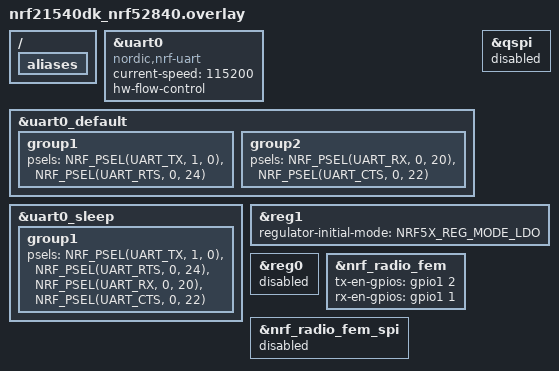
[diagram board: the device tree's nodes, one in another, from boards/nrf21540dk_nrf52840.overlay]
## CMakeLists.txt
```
# SPDX-License-Identifier: Apache-2.0

cmake_minimum_required(VERSION 3.20.0)

find_package(Zephyr REQUIRED HINTS $ENV{ZEPHYR_BASE})
project(hci_uart)

test_sysbuild()

target_sources(app PRIVATE src/main.c src/board.c)
```

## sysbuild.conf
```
# Sysbuild configuration file.

# Enable MCUboot per default for this sample.
SB_CONFIG_PARTITION_MANAGER=y
SB_CONFIG_BOOTLOADER_MCUBOOT=y

SB_CONFIG_MCUBOOT_MODE_SINGLE_APP=y
```

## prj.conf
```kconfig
CONFIG_CONSOLE=n
CONFIG_STDOUT_CONSOLE=n
CONFIG_UART_CONSOLE=n
CONFIG_GPIO=y
CONFIG_SERIAL=y
CONFIG_UART_INTERRUPT_DRIVEN=y
CONFIG_BT=y
CONFIG_BT_HCI_RAW=y
CONFIG_BT_HCI_RAW_H4=y
CONFIG_BT_HCI_RAW_H4_ENABLE=y
CONFIG_BT_BUF_ACL_RX_SIZE=255
CONFIG_BT_BUF_CMD_TX_SIZE=255
CONFIG_BT_BUF_EVT_DISCARDABLE_SIZE=255
CONFIG_BT_CTLR_ASSERT_HANDLER=y
CONFIG_BT_MAX_CONN=16
CONFIG_BT_TINYCRYPT_ECC=n
CONFIG_BT_CTLR_DTM_HCI=y

CONFIG_SYSTEM_WORKQUEUE_STACK_SIZE=512

# Workaround: Unable to allocate command buffer when using K_NO_WAIT since
# Host number of completed commands does not follow normal flow control.
CONFIG_BT_BUF_CMD_TX_COUNT=10

CONFIG_CLOCK_CONTROL_NRF_K32SRC_XTAL=n
CONFIG_CLOCK_CONTROL_NRF_K32SRC_RC=y
CONFIG_CLOCK_CONTROL_NRF_K32SRC_500PPM=y

#####################################################
###### To be compatible with AzureWave module #######
####### by enbaling PARAM REQ to support IOS ########
#####################################################

# BT_CTLR_CONN_PARAM_REQ_SUPPORT=y
# CONFIG_BOOTLOADER_MCUBOOT=y
# CONFIG_SINGLE_APPLICATION_SLOT=y

CONFIG_BT_CTLR_CONN_PARAM_REQ=y
CONFIG_BT_CTLR_ADVANCED_FEATURES=n
CONFIG_BT_CTLR_PER_INIT_FEAT_XCHG=y

CONFIG_BT_PHY_UPDATE=y
CONFIG_BT_CTLR_PHY_2M=y
CONFIG_BT_CTLR_PHY_CODED=y

# CONFIG_BT_BUF_EVT_RX_COUNT=16
CONFIG_BT_BUF_EVT_RX_COUNT=8

CONFIG_BT_BUF_EVT_RX_SIZE=255
CONFIG_BT_BUF_ACL_RX_SIZE=255
CONFIG_BT_BUF_ACL_TX_SIZE=251
CONFIG_BT_BUF_CMD_TX_SIZE=255

# Host and Controller common dependencies
CONFIG_BT_EXT_ADV=n
CONFIG_BT_PER_ADV=n
CONFIG_BT_PER_ADV_SYNC=n
# CONFIG_BT_PER_ADV_SYNC_MAX=2

# Broadcast and Connected ISO
# CONFIG_BT_ISO_BROADCASTER=y
# CONFIG_BT_ISO_SYNC_RECEIVER=y
# CONFIG_BT_ISO_CENTRAL=y
# CONFIG_BT_ISO_PERIPHERAL=y

# ISO Streams
# CONFIG_BT_ISO_MAX_CHAN=2

# Controller
CONFIG_BT_LL_SW_SPLIT=y
CONFIG_BT_CTLR_ASSERT_HANDLER=y
CONFIG_BT_CTLR_DTM_HCI=n

# Rx ACL and Adv Reports
CONFIG_BT_CTLR_RX_BUFFERS=9
CONFIG_BT_CTLR_DATA_LENGTH_MAX=251

# Advertising Sets and Extended Scanning
CONFIG_BT_CTLR_ADV_EXT=n
# CONFIG_BT_CTLR_ADV_EXT=y
# CONFIG_BT_CTLR_ADV_SET=3
# CONFIG_BT_CTLR_ADV_DATA_LEN_MAX=191
# CONFIG_BT_CTLR_SCAN_DATA_LEN_MAX=1650

CONFIG_BT_CTLR_ADVANCED_FEATURES=n
# CONFIG_BT_CTLR_ADV_AUX_SET=3
CONFIG_BT_CTLR_ADV_AUX_PDU_BACK2BACK=n
# CONFIG_BT_CTLR_ADV_SYNC_SET=3
CONFIG_BT_CTLR_ADV_SYNC_PDU_BACK2BACK=n
# CONFIG_BT_CTLR_ADV_DATA_BUF_MAX=6

# Increase the below to receive interleaved advertising chains
CONFIG_BT_CTLR_SCAN_AUX_SET=1

CONFIG_BT_CTLR_ADV_RESERVE_MAX=n
CONFIG_BT_CTLR_CENTRAL_RESERVE_MAX=n
CONFIG_BT_CTLR_SLOT_RESERVATION_UPDATE=n
CONFIG_BT_CTLR_SCAN_UNRESERVED=n
CONFIG_BT_TICKER_NEXT_SLOT_GET_MATCH=n
CONFIG_BT_TICKER_EXT=n
CONFIG_BT_TICKER_EXT_SLOT_WINDOW_YIELD=n

# Control Procedure
CONFIG_BT_CTLR_LLCP_LOCAL_PROC_CTX_BUF_NUM=6

# Direction Finding
CONFIG_BT_CTLR_DF=n
# CONFIG_BT_CTLR_DF_PER_ADV_CTE_NUM_MAX=3
# CONFIG_BT_CTLR_DF_PER_SCAN_CTE_NUM_MAX=3

# Direction Finding Tx
CONFIG_BT_CTLR_DF_CTE_TX=n
# CONFIG_BT_CTLR_DF_CONN_CTE_TX=y
# CONFIG_BT_CTLR_DF_ANT_SWITCH_TX=y
# CONFIG_BT_CTLR_DF_CONN_CTE_RSP=y

# Direction Finding Rx
CONFIG_BT_CTLR_DF_CTE_RX=n
# CONFIG_BT_CTLR_DF_CONN_CTE_RX=y
# CONFIG_BT_CTLR_DF_ANT_SWITCH_RX=y
# CONFIG_BT_CTLR_DF_CONN_CTE_REQ=y

# ISO Broadcaster Controller
CONFIG_BT_CTLR_ADV_EXT=n
# CONFIG_BT_CTLR_ADV_PERIODIC=y
# CONFIG_BT_CTLR_ADV_ISO=y
# CONFIG_BT_CTLR_ADV_ISO_PDU_LEN_MAX=247
# CONFIG_BT_CTLR_ADV_ISO_STREAM_MAX=2

# ISO Receive Controller
CONFIG_BT_CTLR_ADV_EXT=n
# CONFIG_BT_CTLR_SYNC_PERIODIC=y
# CONFIG_BT_CTLR_SYNC_ISO=y
# CONFIG_BT_CTLR_SYNC_ISO_PDU_LEN_MAX=251
# CONFIG_BT_CTLR_SYNC_ISO_STREAM_MAX=2

# ISO Connection Oriented
CONFIG_BT_CTLR_CENTRAL_ISO=n
CONFIG_BT_CTLR_PERIPHERAL_ISO=n
# CONFIG_BT_CTLR_CONN_ISO_SDU_LEN_MAX=247
# CONFIG_BT_CTLR_CONN_ISO_PDU_LEN_MAX=251

# ISO Transmissions
# CONFIG_BT_CTLR_ISO_TX_BUFFERS=8
# CONFIG_BT_CTLR_ISO_TX_BUFFER_SIZE=255
# CONFIG_BT_CTLR_ISOAL_SOURCES=2

# ISO Receptions
# CONFIG_BT_CTLR_ISO_RX_BUFFERS=8
# CONFIG_BT_CTLR_ISOAL_SINKS=2

# Tx Power Dynamic Control
CONFIG_BT_CTLR_TX_PWR_DYNAMIC_CONTROL=y
# CONFIG_BT_CTLR_TX_PWR_PLUS_8=y
# CONFIG_BT_CTLR_TX_PWR_0=y
CONFIG_BT_CTLR_TX_PWR_MINUS_20=y


#############################################################
CONFIG_MCUBOOT_EXTRA_IMGTOOL_ARGS="--version 1.0.3"


# If want to enable logging for debugging stack overflows etc, uncomment below

# # Enable logging via SEGGER RTT so logs appear over J-Link RTT
# CONFIG_LOG=y
# # 2 = Info (disable DBG to reduce log volume).
# CONFIG_LOG_DEFAULT_LEVEL=2
# CONFIG_LOG_BACKEND_RTT=y
# # CONFIG_SEGGER_RTT=y
# # Flush log immediately which helps for early boot / crashes
# # Ensure immediate mode is disabled to avoid blocking contexts
# CONFIG_LOG_MODE_IMMEDIATE=n

# # Increase log processing thread stack to avoid overflow (seen at runtime)
# CONFIG_LOG_PROCESS_THREAD_STACK_SIZE=4096

# # # Enable thread stack debugging to catch overflows and identify threads
# # # Provides runtime info about which thread overflowed and stack usage
# CONFIG_THREAD_MONITOR=y
# CONFIG_THREAD_NAME=y
# CONFIG_STACK_CANARIES=y

# # Increase some stack sizes that commonly overflow in Bluetooth controller use
# # Increase HCI TX thread stack
# CONFIG_BT_HCI_TX_STACK_SIZE_WITH_PROMPT=y
# CONFIG_BT_HCI_TX_STACK_SIZE=4096
# # Increase system workqueue stack
# CONFIG_SYSTEM_WORKQUEUE_STACK_SIZE=1024
# # Increase main thread stack as a precaution
# CONFIG_MAIN_STACK_SIZE=4096

# CONFIG_LOG_BUFFER_SIZE=8192
# CONFIG_SEGGER_RTT_BUFFER_SIZE_UP=8192
# CONFIG_LOG_BACKEND_RTT_MODE_DROP=n
```

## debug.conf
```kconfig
CONFIG_ASSERT=y

CONFIG_THREAD_NAME=y
CONFIG_THREAD_ANALYZER=y
CONFIG_THREAD_ANALYZER_AUTO=y
CONFIG_THREAD_ANALYZER_RUN_UNLOCKED=y

CONFIG_HW_STACK_PROTECTION=y

CONFIG_CONSOLE=y
CONFIG_LOG=y
CONFIG_LOG_BUFFER_SIZE=4096
CONFIG_RTT_CONSOLE=y
CONFIG_LOG_BACKEND_RTT=y
CONFIG_LOG_BACKEND_RTT_MODE_DROP=n
CONFIG_USE_SEGGER_RTT=y
CONFIG_SEGGER_RTT_BUFFER_SIZE_UP=4096
CONFIG_LOG_BACKEND_SHOW_COLOR=n
CONFIG_LOG_PROCESS_THREAD_STACK_SIZE=1024

CONFIG_LOG_DEFAULT_LEVEL=3
```

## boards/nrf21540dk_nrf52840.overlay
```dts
// To get started, press Ctrl+Space to bring up the completion menu and view the available nodes.

// You can also use the buttons in the sidebar to perform actions on nodes.
// Actions currently available include:

// * Enabling / disabling the node
// * Adding the bus to a bus
// * Removing the node
// * Connecting ADC channels

// For more help, browse the DeviceTree documentation at https://docs.zephyrproject.org/latest/guides/dts/index.html
// You can also visit the nRF DeviceTree extension documentation at https://docs.nordicsemi.com/bundle/nrf-connect-vscode/page/guides/ncs_configure_app.html#devicetree-support-in-the-extension

/* SPDX-License-Identifier: Apache-2.0 */

&uart0 {
	compatible = "nordic,nrf-uart";
	current-speed = <115200>;
	status = "okay";
	hw-flow-control;
};

&uart0_default {
	group1 {
		psels = <NRF_PSEL(UART_TX, 1, 0)>, <NRF_PSEL(UART_RTS, 0, 24)>;
		// psels = <NRF_PSEL(UART_TX, 1, 3)>, <NRF_PSEL(UART_RTS, 1, 4)>;
	};

	group2 {
		psels = <NRF_PSEL(UART_RX, 0, 20)>, <NRF_PSEL(UART_CTS, 0, 22)>;
		// psels = <NRF_PSEL(UART_RX, 1, 5)>, <NRF_PSEL(UART_CTS, 1, 6)>;
	};
};

&uart0_sleep {
	group1 {
		psels = <NRF_PSEL(UART_TX, 1, 0)>, <NRF_PSEL(UART_RTS, 0, 24)>, <NRF_PSEL(UART_RX, 0, 20)>, <NRF_PSEL(UART_CTS, 0, 22)>;
		// psels = <NRF_PSEL(UART_TX, 1, 3)>, <NRF_PSEL(UART_RTS, 1, 4)>, <NRF_PSEL(UART_RX, 1, 5)>, <NRF_PSEL(UART_CTS, 1, 6)>;
	};
};

&qspi {
	status = "disabled";
};
/delete-node/ &button2;

/ {
	aliases {
		/delete-property/ sw2;
	};
};

&reg1 {
	regulator-initial-mode = <NRF5X_REG_MODE_LDO>;
    // regulator-initial-mode = <NRF5X_REG_MODE_DCDC>;
};
&reg0 {
    status = "disabled";
    // status = "okay";
};
&nrf_radio_fem {
	tx-en-gpios = <&gpio1 2 GPIO_ACTIVE_HIGH>;
	rx-en-gpios = <&gpio1 1 GPIO_ACTIVE_HIGH>;
	/delete-property/ pdn-gpios;
	/delete-property/ spi-if;
	/delete-property/ mode-gpios;
	/delete-property/ ant-sel-gpios;
};

&nrf_radio_fem_spi {
	status = "disabled";
};
```

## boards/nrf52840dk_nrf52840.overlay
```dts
/* SPDX-License-Identifier: Apache-2.0 */

// &uart0 {
// 	compatible = "nordic,nrf-uart";
// 	current-speed = <115200>;
// 	status = "okay";
// 	hw-flow-control;
// };

// &uart0_default {
// 	group1 {
// 		psels = <NRF_PSEL(UART_TX, 1, 0)>, <NRF_PSEL(UART_RTS, 0, 24)>;
// 	};

// 	group2 {
// 		psels = <NRF_PSEL(UART_RX, 0, 20)>, <NRF_PSEL(UART_CTS, 0, 22)>;
// 	};
// };

// &uart0_sleep {
// 	group1 {
// 		psels = <NRF_PSEL(UART_TX, 1, 0)>, <NRF_PSEL(UART_RTS, 0, 24)>, <NRF_PSEL(UART_RX, 0, 20)>, <NRF_PSEL(UART_CTS, 0, 22)>;
// 	};
// };

// &qspi {
// 	status = "disabled";
// };
// /delete-node/ &button2;

// / {
// 	aliases {
// 		/delete-property/ sw2;
// 	};
// };

// &reg1 {
// 	regulator-initial-mode = <NRF5X_REG_MODE_LDO>;
//     // regulator-initial-mode = <NRF5X_REG_MODE_DCDC>;
// };
// &reg0 {
//     status = "disabled";
//     // status = "okay";
// };
```

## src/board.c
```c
/*
 * Copyright (c) 2018 Nordic Semiconductor ASA.
 *
 * SPDX-License-Identifier: Apache-2.0
 */
#include <zephyr/kernel.h>
#include <zephyr/arch/cpu.h>
#include <zephyr/sys/byteorder.h>
#include <zephyr/logging/log.h>

#include <zephyr/devicetree.h>
#include <zephyr/dt-bindings/regulator/nrf5x.h>
#include <zephyr/kernel.h>
#include <zephyr/init.h>
#include <hal/nrf_power.h>
#include <soc/nrfx_coredep.h>
#include <zephyr/logging/log.h>

#include <cmsis_core.h>

#include <zephyr/init.h>
#include <hal/nrf_power.h>

// // #define LOG_MODULE_NAME board
// // LOG_MODULE_REGISTER(LOG_MODULE_NAME);

// static int board_nrf52840dongle_nrf52840_init(void)
// {
// 	uint32_t testCnt = 0;
// 	// LOG_DBG("Start");

// 	testCnt++;
// 	// if((testCnt > 0) && (nrf_power_mainregstatus_get(NRF_POWER) ==
// 	//       NRF_POWER_MAINREGSTATUS_HIGH))
// 	// {
// 	// 	return 0;
// 	// }
// 	/* if the nrf52840dongle_nrf52840 board is powered from USB
// 	 * (high voltage mode), GPIO output voltage is set to 1.8 volts by
// 	 * default and that is not enough to turn the green and blue LEDs on.
// 	 * Increase GPIO voltage to 3.0 volts.
// 	 */
// 	// if ((nrf_power_mainregstatus_get(NRF_POWER) ==
// 	//      NRF_POWER_MAINREGSTATUS_HIGH) &&
// 	//     ((NRF_UICR->REGOUT0 & UICR_REGOUT0_VOUT_Msk) ==
// 	//      (UICR_REGOUT0_VOUT_DEFAULT << UICR_REGOUT0_VOUT_Pos))) {
// 	// testCnt++;

// 	// 	NRF_NVMC->CONFIG = NVMC_CONFIG_WEN_Wen << NVMC_CONFIG_WEN_Pos;
// 	// 	while (NRF_NVMC->READY == NVMC_READY_READY_Busy) {
// 	// 		;
// 	// 	}

// 	// 	NRF_UICR->REGOUT0 =
// 	// 	    (NRF_UICR->REGOUT0 & ~((uint32_t)UICR_REGOUT0_VOUT_Msk)) |
// 	// 	    (UICR_REGOUT0_VOUT_1V8 << UICR_REGOUT0_VOUT_Pos);

// 	// 	NRF_NVMC->CONFIG = NVMC_CONFIG_WEN_Ren << NVMC_CONFIG_WEN_Pos;
// 	// 	while (NRF_NVMC->READY == NVMC_READY_READY_Busy) {
// 	// 		;
// 	// 	}

// 	// 	/* a reset is required for changes to take effect */
// 	// 	NVIC_SystemReset();
// 	// }

// 	return 0;
// }

// SYS_INIT(board_nrf52840dongle_nrf52840_init, APPLICATION,
// 	 CONFIG_KERNEL_INIT_PRIORITY_DEVICE);
```
